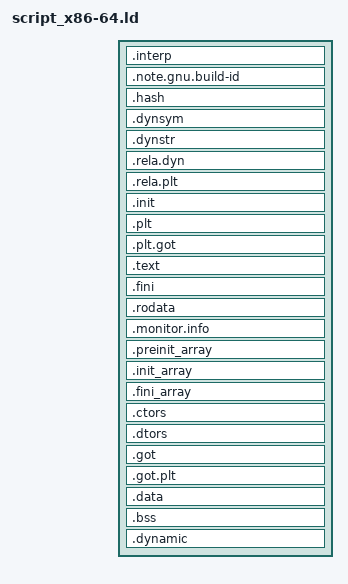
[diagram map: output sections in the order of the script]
OUTPUT_FORMAT("elf64-x86-64", "elf64-x86-64",
              "elf64-x86-64")
OUTPUT_ARCH(i386:x86-64)
ENTRY(_start)
SEARCH_DIR("=/usr/local/lib/x86_64-linux-gnu"); SEARCH_DIR("=/lib/x86_64-linux-gnu"); SEARCH_DIR("=/usr/lib/x86_64-linux-gnu"); SEARCH_DIR("=/usr/lib/x86_64-linux-gnu64"); SEARCH_DIR("=/usr/local/lib64"); SEARCH_DIR("=/lib64"); SEARCH_DIR("=/usr/lib64"); SEARCH_DIR("=/usr/local/lib"); SEARCH_DIR("=/lib"); SEARCH_DIR("=/usr/lib"); SEARCH_DIR("=/usr/x86_64-linux-gnu/lib64"); SEARCH_DIR("=/usr/x86_64-linux-gnu/lib");
PHDRS
{
  text PT_LOAD FILEHDR PHDRS;
  monitor PT_LOAD ;
  data PT_LOAD ;
  dynamic PT_DYNAMIC ;
}
SECTIONS
{
  /* Read-only sections, merged into text segment: */
  PROVIDE (__executable_start = SEGMENT_START("text-segment", 0)); . = SEGMENT_START("text-segment", 0) + SIZEOF_HEADERS;
  .interp         : { *(.interp) } :text
  .note.gnu.build-id : { *(.note.gnu.build-id) }
  .hash           : { *(.hash) }
  .dynsym         : { *(.dynsym) }
  .dynstr         : { *(.dynstr) }
  .rela.dyn       :
    {
      *(.rela.init)
      *(.rela.text .rela.text.* .rela.gnu.linkonce.t.*)
      *(.rela.fini)
      *(.rela.rodata .rela.rodata.* .rela.gnu.linkonce.r.*)
      *(.rela.data .rela.data.* .rela.gnu.linkonce.d.*)
      *(.rela.tdata .rela.tdata.* .rela.gnu.linkonce.td.*)
      *(.rela.tbss .rela.tbss.* .rela.gnu.linkonce.tb.*)
      *(.rela.ctors)
      *(.rela.dtors)
      *(.rela.got)
      *(.rela.bss .rela.bss.* .rela.gnu.linkonce.b.*)
      *(.rela.ldata .rela.ldata.* .rela.gnu.linkonce.l.*)
      *(.rela.lbss .rela.lbss.* .rela.gnu.linkonce.lb.*)
      *(.rela.lrodata .rela.lrodata.* .rela.gnu.linkonce.lr.*)
      *(.rela.ifunc)
    }
  .rela.plt       :
    {
      *(.rela.plt)
      PROVIDE_HIDDEN (__rela_iplt_start = .);
      *(.rela.iplt)
      PROVIDE_HIDDEN (__rela_iplt_end = .);
    }
  .init           :
  {
    KEEP (*(SORT_NONE(.init)))
  }
  .plt            : { *(.plt) *(.iplt) }
  .plt.got        : { *(.plt.got) }
  .text           :
  {
    *(.text.unlikely .text.*_unlikely .text.unlikely.*)
    *(.text.exit .text.exit.*)
    *(.text.startup .text.startup.*)
    *(.text.hot .text.hot.*)
    *(.text .stub .text.* .gnu.linkonce.t.*)
    /* .gnu.warning sections are handled specially by elf32.em.  */
    *(.gnu.warning)
  }
  .fini           :
  {
    KEEP (*(SORT_NONE(.fini)))
  }
  PROVIDE (__etext = .);
  PROVIDE (_etext = .);
  PROVIDE (etext = .);
  
  .rodata         : { *(.rodata .rodata.* .gnu.linkonce.r.*) } /* defaults to :text */


  . = ALIGN(0x1000);
  .monitor.info .      : { *(.monitor.info) } :monitor

  . = ALIGN(0x1000);
  PROVIDE (__bdata = .);
  PROVIDE (_bdata = .);
  PROVIDE (bdata = .);
  .preinit_array     :
  {
    PROVIDE_HIDDEN (__preinit_array_start = .);
    KEEP (*(.preinit_array))
    PROVIDE_HIDDEN (__preinit_array_end = .);
  } :data
  .init_array     :
  {
    PROVIDE_HIDDEN (__init_array_start = .);
    KEEP (*(SORT_BY_INIT_PRIORITY(.init_array.*) SORT_BY_INIT_PRIORITY(.ctors.*)))
    KEEP (*(.init_array EXCLUDE_FILE (*crtbegin.o *crtbegin?.o *crtend.o *crtend?.o ) .ctors))
    PROVIDE_HIDDEN (__init_array_end = .);
  }
  .fini_array     :
  {
    PROVIDE_HIDDEN (__fini_array_start = .);
    KEEP (*(SORT_BY_INIT_PRIORITY(.fini_array.*) SORT_BY_INIT_PRIORITY(.dtors.*)))
    KEEP (*(.fini_array EXCLUDE_FILE (*crtbegin.o *crtbegin?.o *crtend.o *crtend?.o ) .dtors))
    PROVIDE_HIDDEN (__fini_array_end = .);
  }
  .ctors          :
  {
    KEEP (*crtbegin.o(.ctors))
    KEEP (*crtbegin?.o(.ctors))
    KEEP (*(EXCLUDE_FILE (*crtend.o *crtend?.o ) .ctors))
    KEEP (*(SORT(.ctors.*)))
    KEEP (*(.ctors))
  }
  .dtors          :
  {
    KEEP (*crtbegin.o(.dtors))
    KEEP (*crtbegin?.o(.dtors))
    KEEP (*(EXCLUDE_FILE (*crtend.o *crtend?.o ) .dtors))
    KEEP (*(SORT(.dtors.*)))
    KEEP (*(.dtors))
  }

  .got            : { *(.got) *(.igot) }
  .got.plt        : { *(.got.plt)  *(.igot.plt) }
  .data           :
  {
    *(.data .data.* .gnu.linkonce.d.*)
    SORT(CONSTRUCTORS)
  }
  .bss            :
  {
   *(.dynbss)
   *(.bss .bss.* .gnu.linkonce.b.*)
   *(COMMON)
   . = ALIGN(. != 0 ? 64 / 8 : 1);
  }
  .dynamic        : { *(.dynamic) } :dynamic :data
  PROVIDE (__edata = .);
  PROVIDE (_edata = .);
  PROVIDE (edata = .);

  . = ALIGN(64 / 8);
  _end = .;
  PROVIDE (end = .);
}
